# G32R501 register map
Vendor: Geehy Semiconductor Co., Ltd.; Series: G32R5; File version: 1.0
CPU: CM55 r0p1, little endian, MPU, FPU, double-precision FPU, DSP, VTOR, 4 interrupt priority bits
Registers are 32-bit, read-write, reset 0x0 unless marked. A register's access mark holds for its fields unless they carry their own. Offsets are from the block's base; [hi:lo] are bit positions; {n}, {i} and the like mark numbered series.

## DBGMCU
Base 0xE0059000
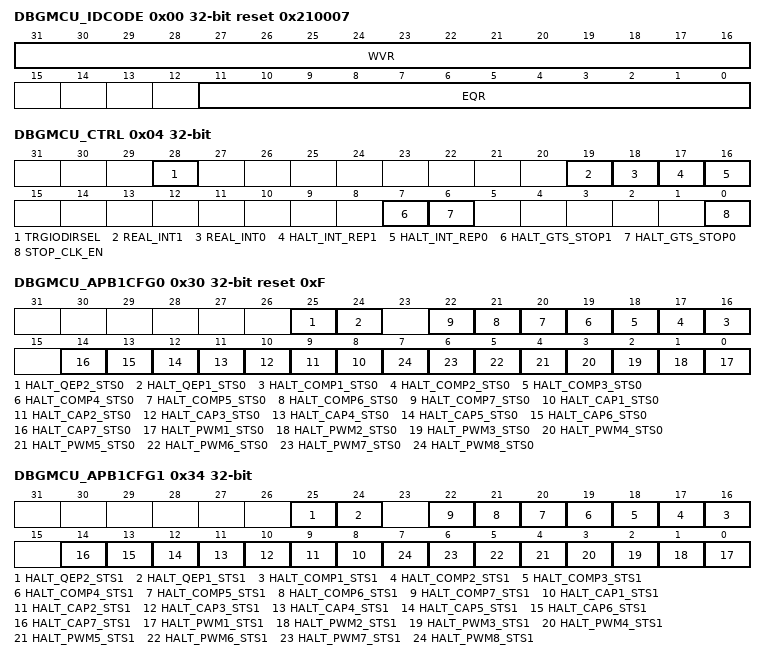
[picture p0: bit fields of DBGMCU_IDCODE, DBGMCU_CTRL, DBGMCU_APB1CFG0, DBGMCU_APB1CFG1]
0x00 DBGMCU_IDCODE reset 0x210007 — Device ID register
  [31:16] WVR — Wafer Version Recognition
  [11:0] EQR — Equipment Recognition
0x04 DBGMCU_CTRL — Debug MCU Control register
  [28] TRGIODIRSEL — TRGIO direction select
  [19] REAL_INT1 — Interrupt run cannot enter HALT when CPU1 in real-time mode
  [18] REAL_INT0 — Interrupt run cannot enter HALT when CPU0 in real-time mode
  [17] HALT_INT_REP1 — The response is interrupt when CPU1 in HALT mode
  [16] HALT_INT_REP0 — The response is interrupt when CPU0 in HALT mode
  [7] HALT_GTS_STOP1 — The global timestamp is stop when CPU1 enters HALT mode
  [6] HALT_GTS_STOP0 — The global timestamp is stop when CPU0 enters HALT mode
  [0] STOP_CLK_EN — Enable the system clock when MCU is debugged in stop mode
0x30 DBGMCU_APB1CFG0 reset 0xF — CPU0 APB1 Debug MCU configuration register
  [25] HALT_QEP2_STS0 — Configure QEP2 work status when CPU0 is in HALT mode
  [24] HALT_QEP1_STS0 — Configure QEP1 work status when CPU0 is in HALT mode
  [n+15] HALT_COMP{n}_STS0 (n=1..7) — Configure COMP{n} work status when CPU0 is in HALT mode
  [n+7] HALT_CAP{n}_STS0 (n=1..7) — Configure CAP{n} work status when CPU0 is in HALT mode
  [n-1] HALT_PWM{n}_STS0 (n=1..8) — Configure PWM{n} work status when CPU0 is in HALT mode
0x34 DBGMCU_APB1CFG1 — CPU1 APB1 Debug MCU configuration register
  [25] HALT_QEP2_STS1 — Configure QEP2 work status when CPU1 is in HALT mode
  [24] HALT_QEP1_STS1 — Configure QEP1 work status when CPU1 is in HALT mode
  [n+15] HALT_COMP{n}_STS1 (n=1..7) — Configure COMP{n} work status when CPU1 is in HALT mode
  [n+7] HALT_CAP{n}_STS1 (n=1..7) — Configure CAP{n} work status when CPU1 is in HALT mode
  [n-1] HALT_PWM{n}_STS1 (n=1..8) — Configure PWM{n} work status when CPU1 is in HALT mode
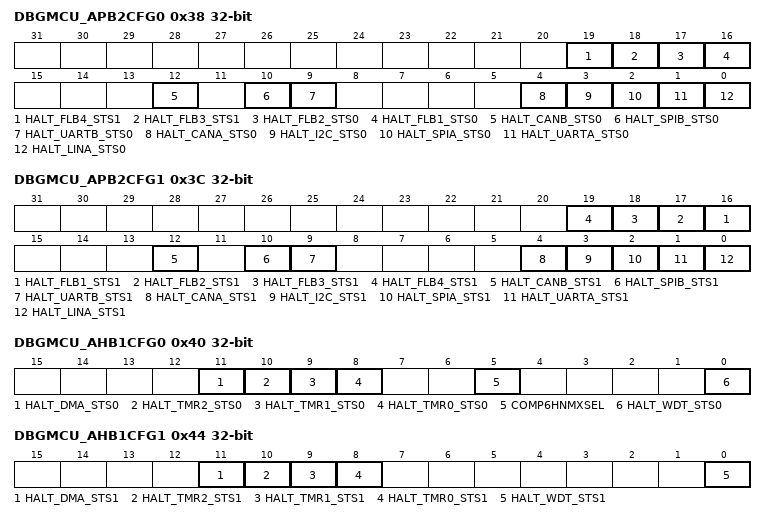
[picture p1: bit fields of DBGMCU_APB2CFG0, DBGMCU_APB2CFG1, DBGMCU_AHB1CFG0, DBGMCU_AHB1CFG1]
0x38 DBGMCU_APB2CFG0 — CPU0 APB2 Debug MCU configuration register
  [19] HALT_FLB4_STS1 — Configure FLB4 work status when CPU1 is in HALT mode
  [18] HALT_FLB3_STS1 — Configure FLB3 work status when CPU1 is in HALT mode
  [17] HALT_FLB2_STS0 — Configure FLB2 work status when CPU0 is in HALT mode
  [16] HALT_FLB1_STS0 — Configure FLB1 work status when CPU0 is in HALT mode
  [12] HALT_CANB_STS0 — Configure CANB work status when CPU0 is in HALT mode
  [10] HALT_SPIB_STS0 — Configure SPIAB work status when CPU0 is in HALT mode
  [9] HALT_UARTB_STS0 — Configure UARTB work status when CPU0 is in HALT mode
  [4] HALT_CANA_STS0 — Configure CANA work status when CPU0 is in HALT mode
  [3] HALT_I2C_STS0 — Configure I2C work status when CPU0 is in HALT mode
  [2] HALT_SPIA_STS0 — Configure SPIA work status when CPU0 is in HALT mode
  [1] HALT_UARTA_STS0 — Configure UARTA work status when CPU0 is in HALT mode
  [0] HALT_LINA_STS0 — Configure LINA work status when CPU0 is in HALT mode
0x3C DBGMCU_APB2CFG1 — CPU1 APB2 Debug MCU configuration register
  [n+15] HALT_FLB{n}_STS1 (n=1..4) — Configure FLB{n} work status when CPU1 is in HALT mode
  [12] HALT_CANB_STS1 — Configure CANB work status when CPU1 is in HALT mode
  [10] HALT_SPIB_STS1 — Configure SPIAB work status when CPU1 is in HALT mode
  [9] HALT_UARTB_STS1 — Configure UARTB work status when CPU1 is in HALT mode
  [4] HALT_CANA_STS1 — Configure CANA work status when CPU1 is in HALT mode
  [3] HALT_I2C_STS1 — Configure I2C work status when CPU1 is in HALT mode
  [2] HALT_SPIA_STS1 — Configure SPIA work status when CPU1 is in HALT mode
  [1] HALT_UARTA_STS1 — Configure UARTA work status when CPU1 is in HALT mode
  [0] HALT_LINA_STS1 — Configure LINA work status when CPU1 is in HALT mode
0x40 DBGMCU_AHB1CFG0 — CPU0 AHB1 Debug MCU configuration register
  [11] HALT_DMA_STS0 — Configure DMA work status when CPU0 is in HALT mode
  [10] HALT_TMR2_STS0 — Configure TMR2 work status when CPU0 is in HALT mode
  [9] HALT_TMR1_STS0 — Configure TMR1 work status when CPU0 is in HALT mode
  [8] HALT_TMR0_STS0 — Configure TMR0 work status when CPU0 is in HALT mode
  [5] COMP6HNMXSEL — Select source on the COMP6_HN input
  [0] HALT_WDT_STS0 — Configure WDT work status when CPU0 is in HALT mode
0x44 DBGMCU_AHB1CFG1 — CPU1 AHB1 Debug MCU configuration register
  [11] HALT_DMA_STS1 — Configure DMA work status when CPU1 is in HALT mode
  [10] HALT_TMR2_STS1 — Configure TMR2 work status when CPU1 is in HALT mode
  [9] HALT_TMR1_STS1 — Configure TMR1 work status when CPU1 is in HALT mode
  [8] HALT_TMR0_STS1 — Configure TMR0 work status when CPU1 is in HALT mode
  [0] HALT_WDT_STS1 — Configure WDT work status when CPU1 is in HALT mode
